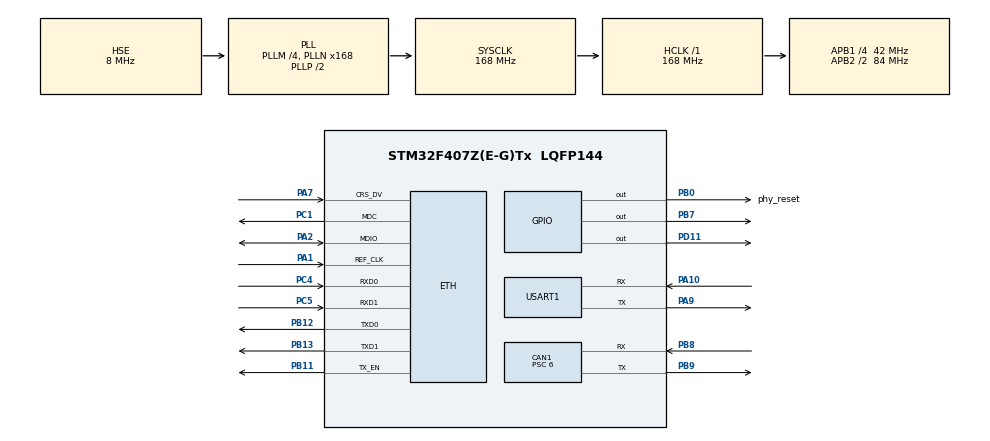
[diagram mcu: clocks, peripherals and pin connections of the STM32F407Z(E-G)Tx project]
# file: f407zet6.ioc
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CAN1.BS1=CAN_BS1_8TQ
CAN1.BS2=CAN_BS2_5TQ
CAN1.CalculateBaudRate=500000
CAN1.CalculateTimeBit=2000
CAN1.CalculateTimeQuantum=142.85714285714286
CAN1.Mode=CAN_MODE_LOOPBACK
CAN1.Prescaler=6
ETH.MediaInterface=HAL_ETH_RMII_MODE
LWIP.BSP.number=1
LWIP.GATEWAY_ADDRESS=192.168.004.001
LWIP.IP_ADDRESS=192.168.004.004
LWIP.LWIP_DHCP=0
LWIP.NETMASK_ADDRESS=255.255.255.000
LWIP.Version=v2.1.2_Cube
LWIP0.BSP.STBoard=false
LWIP0.BSP.api=BSP_COMPONENT_DRIVER
LWIP0.BSP.component=DP83848
LWIP0.BSP.instance=DP83848
LWIP0.BSP.name=Driver_PHY
LWIP0.BSP.semaphore=S_DP83848
LWIP0.BSP.solution=DP83848
Mcu.Family=STM32F4
Mcu.Name=STM32F407Z(E-G)Tx
Mcu.Package=LQFP144
NVIC.CAN1_RX0_IRQn=true\:0\:0\:false\:false\:true\:true\:true\:true
NVIC.ETH_IRQn=true\:0\:0\:false\:false\:true\:true\:true\:true
NVIC.PriorityGroup=NVIC_PRIORITYGROUP_4
NVIC.USART1_IRQn=true\:0\:0\:false\:false\:true\:true\:true\:true
PA1.Mode=RMII
PA1.Signal=ETH_REF_CLK
PA10.Mode=Asynchronous
PA10.Signal=USART1_RX
PA13.Mode=Serial_Wire
PA13.Signal=SYS_JTMS-SWDIO
PA14.Mode=Serial_Wire
PA14.Signal=SYS_JTCK-SWCLK
PA2.Mode=RMII
PA2.Signal=ETH_MDIO
PA7.Mode=RMII
PA7.Signal=ETH_CRS_DV
PA9.Mode=Asynchronous
PA9.Signal=USART1_TX
PB0.GPIO_Label=phy_reset
PB0.GPIO_PuPd=GPIO_PULLUP
PB0.PinState=GPIO_PIN_SET
PB0.Signal=GPIO_Output
PB11.Mode=RMII
PB11.Signal=ETH_TX_EN
PB12.Mode=RMII
PB12.Signal=ETH_TXD0
PB13.Mode=RMII
PB13.Signal=ETH_TXD1
PB7.Signal=GPIO_Output
PB8.Mode=CAN_Activate
PB8.Signal=CAN1_RX
PB9.Mode=CAN_Activate
PB9.Signal=CAN1_TX
PC1.Mode=RMII
PC1.Signal=ETH_MDC
PC14-OSC32_IN.Mode=LSE-External-Oscillator
PC14-OSC32_IN.Signal=RCC_OSC32_IN
PC15-OSC32_OUT.Mode=LSE-External-Oscillator
PC15-OSC32_OUT.Signal=RCC_OSC32_OUT
PC4.Mode=RMII
PC4.Signal=ETH_RXD0
PC5.Mode=RMII
PC5.Signal=ETH_RXD1
PD11.Signal=GPIO_Output
PH0-OSC_IN.Mode=HSE-External-Oscillator
PH0-OSC_IN.Signal=RCC_OSC_IN
PH1-OSC_OUT.Mode=HSE-External-Oscillator
PH1-OSC_OUT.Signal=RCC_OSC_OUT
ProjectManager.HeapSize=0x200
ProjectManager.StackSize=0xC00
ProjectManager.TargetToolchain=MDK-ARM V5.32
RCC.48MHZClocksFreq_Value=84000000
RCC.AHBFreq_Value=168000000
RCC.APB1CLKDivider=RCC_HCLK_DIV4
RCC.APB1Freq_Value=42000000
RCC.APB1TimFreq_Value=84000000
RCC.APB2CLKDivider=RCC_HCLK_DIV2
RCC.APB2Freq_Value=84000000
RCC.APB2TimFreq_Value=168000000
RCC.CortexFreq_Value=168000000
RCC.HCLKFreq_Value=168000000
RCC.HSE_VALUE=8000000
RCC.HSI_VALUE=16000000
RCC.PLLM=4
RCC.PLLN=168
RCC.PLLSourceVirtual=RCC_PLLSOURCE_HSE
RCC.SYSCLKFreq_VALUE=168000000
RCC.SYSCLKSource=RCC_SYSCLKSOURCE_PLLCLK
RCC.VCOOutputFreq_Value=336000000
USART1.VirtualMode=VM_ASYNC
VP_LWIP_VS_Enabled.Mode=Enabled
board=custom

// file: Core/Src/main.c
/* USER CODE BEGIN Header */
/**
  ******************************************************************************
  * @file           : main.c
  * @brief          : Main program body
  ******************************************************************************
  * @attention
  *
  * Copyright (c) 2026 STMicroelectronics.
  * All rights reserved.
  *
  * This software is licensed under terms that can be found in the LICENSE file
  * in the root directory of this software component.
  * If no LICENSE file comes with this software, it is provided AS-IS.
  *
  ******************************************************************************
  */
/* USER CODE END Header */
#include "main.h"
#include "can.h"
#include "lwip.h"
#include "usart.h"
#include "gpio.h"

/* USER CODE BEGIN Includes */
#include "period.h"
/* USER CODE END Includes */

void SystemClock_Config(void);

int main(void)
{

  /* MCU Configuration--------------------------------------------------------*/

  /* Reset of all peripherals, Initializes the Flash interface and the Systick. */
  HAL_Init();

  /* Configure the system clock */
  SystemClock_Config();

  /* Initialize all configured peripherals */
  MX_GPIO_Init();
  MX_LWIP_Init();
  MX_USART1_UART_Init();
  MX_CAN1_Init();
  /* USER CODE BEGIN 2 */
	All_Task_Init();
  /* USER CODE END 2 */

  /* Infinite loop */
  /* USER CODE BEGIN WHILE */
  while (1)
  {
		periodic_event_task_process();
    /* USER CODE END WHILE */

  }
}

void SystemClock_Config(void)
{
  RCC_OscInitTypeDef RCC_OscInitStruct = {0};
  RCC_ClkInitTypeDef RCC_ClkInitStruct = {0};

  /** Configure the main internal regulator output voltage
  */
  __HAL_RCC_PWR_CLK_ENABLE();
  __HAL_PWR_VOLTAGESCALING_CONFIG(PWR_REGULATOR_VOLTAGE_SCALE1);

  /** Initializes the RCC Oscillators according to the specified parameters
  * in the RCC_OscInitTypeDef structure.
  */
  RCC_OscInitStruct.OscillatorType = RCC_OSCILLATORTYPE_HSE;
  RCC_OscInitStruct.HSEState = RCC_HSE_ON;
  RCC_OscInitStruct.PLL.PLLState = RCC_PLL_ON;
  RCC_OscInitStruct.PLL.PLLSource = RCC_PLLSOURCE_HSE;
  RCC_OscInitStruct.PLL.PLLM = 4;
  RCC_OscInitStruct.PLL.PLLN = 168;
  RCC_OscInitStruct.PLL.PLLP = RCC_PLLP_DIV2;
  RCC_OscInitStruct.PLL.PLLQ = 4;
  if (HAL_RCC_OscConfig(&RCC_OscInitStruct) != HAL_OK)
  {
    Error_Handler();
  }

  /** Initializes the CPU, AHB and APB buses clocks
  */
  RCC_ClkInitStruct.ClockType = RCC_CLOCKTYPE_HCLK|RCC_CLOCKTYPE_SYSCLK
                              |RCC_CLOCKTYPE_PCLK1|RCC_CLOCKTYPE_PCLK2;
  RCC_ClkInitStruct.SYSCLKSource = RCC_SYSCLKSOURCE_PLLCLK;
  RCC_ClkInitStruct.AHBCLKDivider = RCC_SYSCLK_DIV1;
  RCC_ClkInitStruct.APB1CLKDivider = RCC_HCLK_DIV4;
  RCC_ClkInitStruct.APB2CLKDivider = RCC_HCLK_DIV2;

  if (HAL_RCC_ClockConfig(&RCC_ClkInitStruct, FLASH_LATENCY_5) != HAL_OK)
  {
    Error_Handler();
  }
}

/* USER CODE BEGIN 4 */
int fputc(int ch, FILE *f)
{
  // �������Ĵ��� 1 ����� huart1��CubeMX Ĭ�����ɵ����ƣ�
  // ���ʹ�õ��Ǵ��� 2�����Ϊ &huart2
  HAL_UART_Transmit(&huart1, (uint8_t *)&ch, 1, 0xFFFF);
  return ch;
}
/* USER CODE END 4 */

void Error_Handler(void)
{
  __disable_irq();
  while (1)
  {
  }
}
